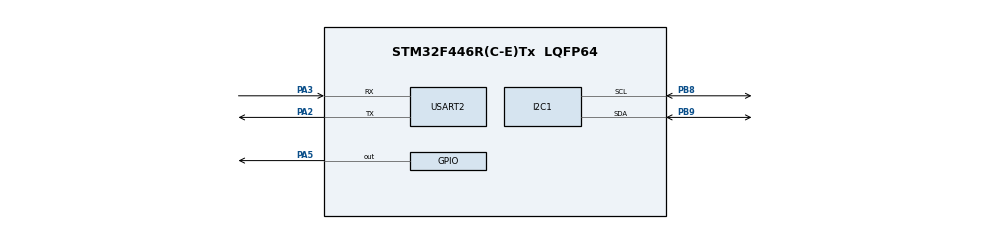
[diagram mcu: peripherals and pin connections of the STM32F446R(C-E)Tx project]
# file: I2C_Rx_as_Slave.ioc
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I2C1.GeneralCallMode=I2C_GENERALCALL_ENABLE
I2C1.OwnAddress=14
Mcu.Family=STM32F4
Mcu.Name=STM32F446R(C-E)Tx
Mcu.Package=LQFP64
NVIC.I2C1_EV_IRQn=true\:0\:0\:false\:false\:true\:true\:true
NVIC.PriorityGroup=NVIC_PRIORITYGROUP_4
PA13.Mode=Serial_Wire
PA13.Signal=SYS_JTMS-SWDIO
PA14.Mode=Serial_Wire
PA14.Signal=SYS_JTCK-SWCLK
PA2.Mode=Asynchronous
PA2.Signal=USART2_TX
PA3.Mode=Asynchronous
PA3.Signal=USART2_RX
PA5.Signal=GPIO_Output
PB8.GPIO_Pu=GPIO_NOPULL
PB8.Mode=I2C
PB8.Signal=I2C1_SCL
PB9.GPIO_Pu=GPIO_NOPULL
PB9.Mode=I2C
PB9.Signal=I2C1_SDA
PC14-OSC32_IN.Mode=LSE-External-Oscillator
PC14-OSC32_IN.Signal=RCC_OSC32_IN
PC15-OSC32_OUT.Mode=LSE-External-Oscillator
PC15-OSC32_OUT.Signal=RCC_OSC32_OUT
PH0-OSC_IN.Mode=HSE-External-Oscillator
PH0-OSC_IN.Signal=RCC_OSC_IN
PH1-OSC_OUT.Mode=HSE-External-Oscillator
PH1-OSC_OUT.Signal=RCC_OSC_OUT
ProjectManager.HeapSize=0x200
ProjectManager.StackSize=0x400
ProjectManager.TargetToolchain=STM32CubeIDE
RCC.CortexFreq_Value=16000000
RCC.USBFreq_Value=96000000
RCC.VCOOutputFreq_Value=192000000
USART2.VirtualMode=VM_ASYNC
board=custom

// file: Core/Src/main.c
/* USER CODE BEGIN Header */
/**
  ******************************************************************************
  * @file           : main.c
  * @brief          : Main program body
  ******************************************************************************
  * @attention
  *
  * <h2><center>&copy; Copyright (c) 2021 STMicroelectronics.
  * All rights reserved.</center></h2>
  *
  * This software component is licensed by ST under BSD 3-Clause license,
  * the "License"; You may not use this file except in compliance with the
  * License. You may obtain a copy of the License at:
  *                        opensource.org/licenses/BSD-3-Clause
  *
  ******************************************************************************
  */
/* USER CODE END Header */
#include "main.h"

I2C_HandleTypeDef hi2c1;

UART_HandleTypeDef huart2;

/* USER CODE BEGIN PV */
uint8_t rx_msg[12];
int flag=0;

/* USER CODE END PV */

void SystemClock_Config(void);
static void MX_GPIO_Init(void);
static void MX_I2C1_Init(void);
static void MX_USART2_UART_Init(void);
/* USER CODE BEGIN PFP */
void HAL_I2C_SlaveRxCpltCallback(I2C_HandleTypeDef * hi2c)
{

	 HAL_UART_Transmit(&huart2,(uint8_t *)rx_msg,sizeof(rx_msg),100);
	 HAL_GPIO_TogglePin(GPIOA,GPIO_PIN_5);
	 HAL_I2C_Slave_Receive_IT(&hi2c1, (uint8_t *)rx_msg, sizeof(rx_msg));
	//flag=1;
}

/* USER CODE END PFP */

int main(void)
{

  /* MCU Configuration--------------------------------------------------------*/

  /* Reset of all peripherals, Initializes the Flash interface and the Systick. */
    HAL_Init();

  /* Configure the system clock */
  SystemClock_Config();

  /* Initialize all configured peripherals */
  MX_GPIO_Init();
  MX_I2C1_Init();
  MX_USART2_UART_Init();
  /* USER CODE BEGIN 2 */
  HAL_I2C_Init(&hi2c1);
  HAL_I2C_Slave_Receive_IT(&hi2c1, (uint8_t *)rx_msg, sizeof(rx_msg));
  /* USER CODE END 2 */

  /* Infinite loop */
  while (1)
  {

    /* USER CODE BEGIN 3 */
//	        if(flag==1)
//	        {
//	        	if((HAL_I2C_Slave_Receive(&hi2c1, (uint8_t *)rx_msg, sizeof(rx_msg), HAL_MAX_DELAY))==HAL_OK)
//	             {
//	        		 HAL_UART_Transmit(&huart2,(uint8_t *)rx_msg,sizeof(rx_msg),100);
//	        		 HAL_GPIO_TogglePin(GPIOA, GPIO_PIN_5);
//	        	     HAL_Delay(1000);
//	        	 }
//	        }
//	        flag=0;
  }
  /* USER CODE END 3 */
}

void SystemClock_Config(void)
{
  RCC_OscInitTypeDef RCC_OscInitStruct = {0};
  RCC_ClkInitTypeDef RCC_ClkInitStruct = {0};

  /** Configure the main internal regulator output voltage
  */
  __HAL_RCC_PWR_CLK_ENABLE();
  __HAL_PWR_VOLTAGESCALING_CONFIG(PWR_REGULATOR_VOLTAGE_SCALE3);
  /** Initializes the RCC Oscillators according to the specified parameters
  * in the RCC_OscInitTypeDef structure.
  */
  RCC_OscInitStruct.OscillatorType = RCC_OSCILLATORTYPE_HSI;
  RCC_OscInitStruct.HSIState = RCC_HSI_ON;
  RCC_OscInitStruct.HSICalibrationValue = RCC_HSICALIBRATION_DEFAULT;
  RCC_OscInitStruct.PLL.PLLState = RCC_PLL_NONE;
  if (HAL_RCC_OscConfig(&RCC_OscInitStruct) != HAL_OK)
  {
    Error_Handler();
  }
  /** Initializes the CPU, AHB and APB buses clocks
  */
  RCC_ClkInitStruct.ClockType = RCC_CLOCKTYPE_HCLK|RCC_CLOCKTYPE_SYSCLK
                              |RCC_CLOCKTYPE_PCLK1|RCC_CLOCKTYPE_PCLK2;
  RCC_ClkInitStruct.SYSCLKSource = RCC_SYSCLKSOURCE_HSI;
  RCC_ClkInitStruct.AHBCLKDivider = RCC_SYSCLK_DIV1;
  RCC_ClkInitStruct.APB1CLKDivider = RCC_HCLK_DIV1;
  RCC_ClkInitStruct.APB2CLKDivider = RCC_HCLK_DIV1;

  if (HAL_RCC_ClockConfig(&RCC_ClkInitStruct, FLASH_LATENCY_0) != HAL_OK)
  {
    Error_Handler();
  }
}

static void MX_I2C1_Init(void)
{

  hi2c1.Instance = I2C1;
  hi2c1.Init.ClockSpeed = 100000;
  hi2c1.Init.DutyCycle = I2C_DUTYCYCLE_2;
  hi2c1.Init.OwnAddress1 = 28;
  hi2c1.Init.AddressingMode = I2C_ADDRESSINGMODE_7BIT;
  hi2c1.Init.DualAddressMode = I2C_DUALADDRESS_DISABLE;
  hi2c1.Init.OwnAddress2 = 0;
  hi2c1.Init.GeneralCallMode = I2C_GENERALCALL_ENABLE;
  hi2c1.Init.NoStretchMode = I2C_NOSTRETCH_DISABLE;
  if (HAL_I2C_Init(&hi2c1) != HAL_OK)
  {
    Error_Handler();
  }

}

static void MX_USART2_UART_Init(void)
{

  huart2.Instance = USART2;
  huart2.Init.BaudRate = 115200;
  huart2.Init.WordLength = UART_WORDLENGTH_8B;
  huart2.Init.StopBits = UART_STOPBITS_1;
  huart2.Init.Parity = UART_PARITY_NONE;
  huart2.Init.Mode = UART_MODE_TX_RX;
  huart2.Init.HwFlowCtl = UART_HWCONTROL_NONE;
  huart2.Init.OverSampling = UART_OVERSAMPLING_16;
  if (HAL_UART_Init(&huart2) != HAL_OK)
  {
    Error_Handler();
  }

}

static void MX_GPIO_Init(void)
{
  GPIO_InitTypeDef GPIO_InitStruct = {0};

  /* GPIO Ports Clock Enable */
  __HAL_RCC_GPIOC_CLK_ENABLE();
  __HAL_RCC_GPIOH_CLK_ENABLE();
  __HAL_RCC_GPIOA_CLK_ENABLE();
  __HAL_RCC_GPIOB_CLK_ENABLE();

  /*Configure GPIO pin Output Level */
  HAL_GPIO_WritePin(GPIOA, GPIO_PIN_5, GPIO_PIN_RESET);

  /*Configure GPIO pin : PA5 */
  GPIO_InitStruct.Pin = GPIO_PIN_5;
  GPIO_InitStruct.Mode = GPIO_MODE_OUTPUT_PP;
  GPIO_InitStruct.Pull = GPIO_NOPULL;
  GPIO_InitStruct.Speed = GPIO_SPEED_FREQ_LOW;
  HAL_GPIO_Init(GPIOA, &GPIO_InitStruct);

}

void Error_Handler(void)
{
  __disable_irq();
  while (1)
  {
  }
}

/************************ (C) COPYRIGHT STMicroelectronics *****END OF FILE****/
